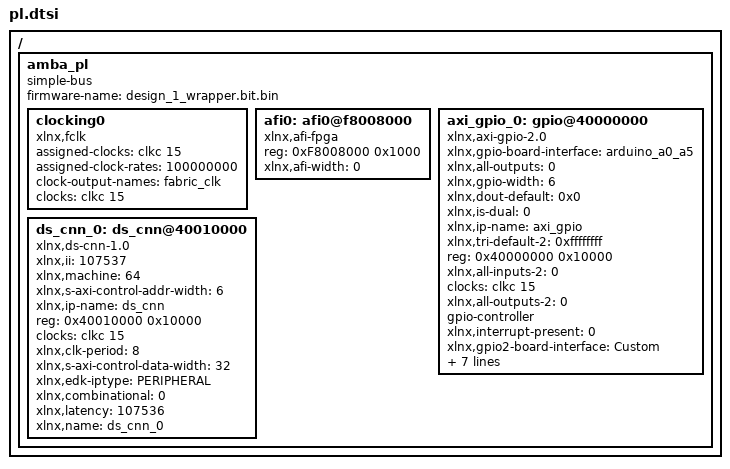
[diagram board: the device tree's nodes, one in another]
/ {
	amba_pl: amba_pl {
		ranges;
		compatible = "simple-bus";
		#address-cells = <1>;
		#size-cells = <1>;
		firmware-name = "design_1_wrapper.bit.bin";
		clocking0: clocking0 {
			compatible = "xlnx,fclk";
			assigned-clocks = <&clkc 15>;
			assigned-clock-rates = <100000000>;
			#clock-cells = <0>;
			clock-output-names = "fabric_clk";
			clocks = <&clkc 15>;
		};
		afi0: afi0@f8008000 {
			status = "okay";
			compatible = "xlnx,afi-fpga";
			#address-cells = <1>;
			reg = <0xF8008000 0x1000>;
			#size-cells = <0>;
			xlnx,afi-width = <0>;
		};
		axi_gpio_0: gpio@40000000 {
			xlnx,gpio-board-interface = "arduino_a0_a5";
			compatible = "xlnx,axi-gpio-2.0" , "xlnx,xps-gpio-1.00.a";
			xlnx,all-outputs = <0>;
			#gpio-cells = <2>;
			xlnx,gpio-width = <6>;
			xlnx,dout-default = <0x0>;
			xlnx,is-dual = <0>;
			xlnx,ip-name = "axi_gpio";
			xlnx,tri-default-2 = <0xffffffff>;
			reg = <0x40000000 0x10000>;
			xlnx,all-inputs-2 = <0>;
			clocks = <&clkc 15>;
			xlnx,all-outputs-2 = <0>;
			gpio-controller;
			device_type = "gpio";
			xlnx,interrupt-present = <0>;
			xlnx,gpio2-board-interface = "Custom";
			xlnx,edk-iptype = "PERIPHERAL";
			xlnx,dout-default-2 = <0x0>;
			status = "okay";
			xlnx,gpio2-width = <32>;
			clock-names = "s_axi_aclk";
			xlnx,use-board-flow;
			xlnx,tri-default = <0xffffffff>;
			xlnx,name = "axi_gpio_0";
			xlnx,all-inputs = <0>;
		};
		ds_cnn_0: ds_cnn@40010000 {
			compatible = "xlnx,ds-cnn-1.0";
			xlnx,ii = <107537>;
			xlnx,machine = <64>;
			xlnx,s-axi-control-addr-width = <6>;
			xlnx,ip-name = "ds_cnn";
			reg = <0x40010000 0x10000>;
			clocks = <&clkc 15>;
			xlnx,clk-period = <8>;
			xlnx,s-axi-control-data-width = <32>;
			xlnx,edk-iptype = "PERIPHERAL";
			status = "okay";
			clock-names = "ap_clk";
			xlnx,combinational = <0>;
			xlnx,latency = <107536>;
			xlnx,name = "ds_cnn_0";
		};
	};
};
